# ARMv8M-Baseline register map
Registers are read-only, no defined reset value unless marked. A register's access mark holds for its fields unless they carry their own. Offsets are from the block's base; [hi:lo] are bit positions.

## FP — Floating-Point Extension
Base 0xE000EF34
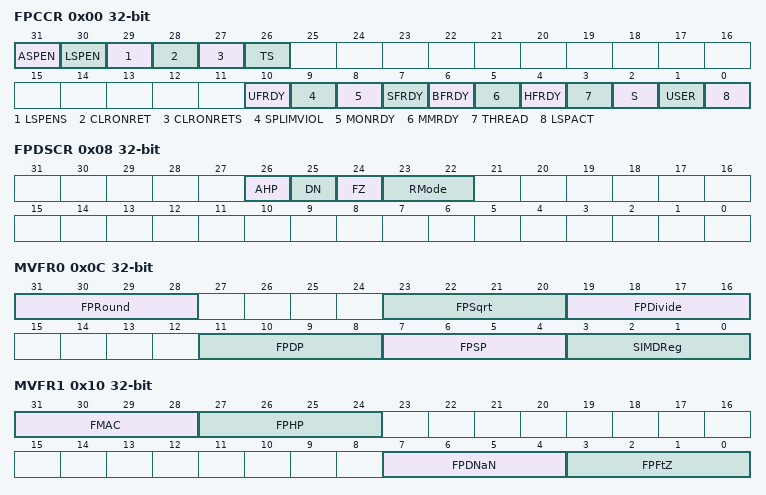
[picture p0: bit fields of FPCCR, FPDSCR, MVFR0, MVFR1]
0x00 FPCCR rw — Floating-Point Context Control Register holds control data for the Floating-point extension
  [31] ASPEN — Automatic state preservation enable
    0=Executing a floating-point instruction has no effect on CONTROL.FPCA; 1=Executing a floating-point instruction sets CONTROL.FPCA to 1
  [30] LSPEN — Lazy state preservation enable. Enables lazy context save of floating-point state
    0=Disable automatic lazy context save; 1=Enable automatic lazy context save
  [29] LSPENS — Lazy state preservation enable Secure only
    0=LSPEN is readable and writeable from both Security states; 1=LSPEN is readable from both Security states, but writes to LSPEN are ignored from the Non-secure state
  [28] CLRONRET — Clear on return. Clear floating-point caller saved registers on exception return
    0=Disabled; 1=Enabled
  [27] CLRONRETS — Clear on return Secure only
    0=The CLRONRET field is accessibly from both Security states; 1=The Non-secure view of the CLRONRET field is read-only
  [26] TS — Treat as Secure. Treat floating-point registers as Secure enable
    0=Disabled; 1=Enabled
  [10] UFRDY — UsageFault ready
    0=Not able to set the UsageFault exception to pending; 1=Able to set the UsageFault exception to pending
  [9] SPLIMVIOL — Stack pointer limit violation
    0=The existing behavior is retained; 1=The memory accesses associated with the floating-point state preservation are not performed
  [8] MONRDY — DebugMonitor ready
    0=Not able to set the DebugMonitor exception to pending; 1=Able to set the DebugMonitor exception to pending
  [7] SFRDY — SecureFault ready
  [6] BFRDY — BusFault ready
    0=Not able to set the BusFault exception to pending; 1=Able to set the BusFault exception to pending
  [5] MMRDY — MemManage ready
    0=Not able to set the MemManage exception to pending; 1=Able to set the MemManage exception to pending
  [4] HFRDY — HardFault ready
    0=Not able to set the HardFault exception to pending; 1=Able to set the HardFault exception to pending
  [3] THREAD — Thread mode. Indicates the PE mode when it allocated the floating-point stack frame
    0=Handler mode; 1=Thread mode
  [2] S — Security. Security status of the floating-point context
    0=Indicates the floating-point context belongs to the Non-secure state; 1=Indicates the floating-point context belongs to the Secure state
  [1] USER — User privilege
    0=Privileged; 1=Unprivileged
  [0] LSPACT — Lazy state preservation active
    0=Lazy state preservation is not active; 1=Lazy state preservation is active
0x04 FPCAR rw — Floating-Point Context Address Register holds the location of the unpopulated floating-point register space allocated on an exception stack frame
  [31:3] ADDRESS
0x08 FPDSCR rw — Floating-Point Default Status Control Register holds the default values for the floating-point status control data that the PE assigns to the FPSCR when it creates a new floating-point context
  [26] AHP — Alternative half-precision. Default value for FPSCR.AHP
  [25] DN — Default NaN. Default value for FPSCR.DN
  [24] FZ — Flush-to-zero. Default value for FPSCR.FZ
  [23:22] RMode — Rounding mode. Default value for FPSCR.RMode
0x0C MVFR0 — Media and VFP Feature Register 0 describes the features provided by the Floating-point Extension
  [31:28] FPRound — Floating-point rounding modes. Indicates the rounding modes supported by the FP Extension
    1=All rounding modes supported
  [23:20] FPSqrt — Floating-point square root. Indicates the support for FP square root operations
    1=Supported
  [19:16] FPDivide — Floating-point divide. Indicates the support for FP divide operations
    1=Supported; 0=3SIMDReg4 7FPSP8 11FPDP12 15RES016 19FPDivide20 23FPSqrt24 27RES028 31FPRoundD1 Register Specification D1
  [11:8] FPDP — Floating-point double-precision. Indicates support for FP double-precision operations
    0=Not supported; 2=Supported
  [7:4] FPSP — Floating-point single-precision. Indicates support for FP single-precision operations
    2=Supported
  [3:0] SIMDReg — SIMD registers. Indicates size of FP register file
    1=16 × 64-bit registers
0x10 MVFR1 — Media and VFP Feature Register 1 describes the features provided by the Floating-point Extension
  [31:28] FMAC — Fused multiply accumulate
    1=Implemented
  [27:24] FPHP — Floating-point half-precision
    1=Half-precision to single-precision implemented; 2=Half-precision to single and double-precision implemented
  [7:4] FPDNaN — Floating-point default NaN
    1=Propagation of NaN values supported
  [3:0] FPFtZ — Floating-point flush-to-zero. Indicates whether subnormals are always flushed-to-zero
    1=Full denormalized numbers arithmetic supported
0x14 MVFR2 — Media and VFP Feature Register 2 describes the features provided by the Floating-point Extension
  [7:4] FPMisc — Floating-point miscellaneous. Indicates support for miscellaneous FP features
    4=Selection, directed conversion to integer, VMINNM and VMAXNM supported
